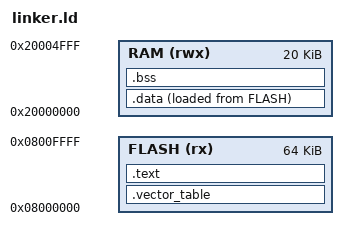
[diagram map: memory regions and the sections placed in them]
ENTRY(reset_handler)

MEMORY
{
  FLASH (rx)  : ORIGIN = 0x08000000, LENGTH = 64K
  RAM   (rwx) : ORIGIN = 0x20000000, LENGTH = 20K
}

SECTIONS
{
  .vector_table ORIGIN(FLASH) :
  {
    KEEP(*(.vector_table))
  } > FLASH

  .text :
  {
    *(.text*)
    *(.rodata*)
  } > FLASH

  .data :
  {
    *(.data*)
  } > RAM AT > FLASH

  .bss (NOLOAD) :
  {
    *(.bss*)
    *(COMMON)
  } > RAM
}

